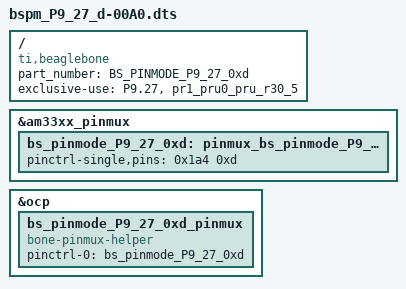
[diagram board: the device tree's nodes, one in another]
/*
 * This is a template-generated file from BoneScript
 */

/dts-v1/;
/plugin/;

/{
    compatible = "ti,beaglebone", "ti,beaglebone-black";
    part_number = "BS_PINMODE_P9_27_0xd";

    exclusive-use =
        "P9.27",
        "pr1_pru0_pru_r30_5";

    fragment@0 {
        target = <&am33xx_pinmux>;
        __overlay__ {
            bs_pinmode_P9_27_0xd: pinmux_bs_pinmode_P9_27_0xd {
                pinctrl-single,pins = <0x1a4 0xd>;
            };
        };
    };

    fragment@1 {
        target = <&ocp>;
        __overlay__ {
            bs_pinmode_P9_27_0xd_pinmux {
                compatible = "bone-pinmux-helper";
                status = "okay";
                pinctrl-names = "default";
                pinctrl-0 = <&bs_pinmode_P9_27_0xd>;
            };
        };
    };
};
